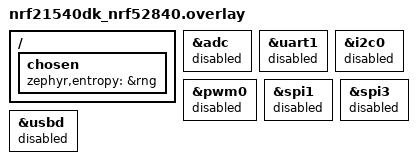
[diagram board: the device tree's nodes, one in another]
/* Copyright (c) 2021 Nordic Semiconductor ASA
 *
 * SPDX-License-Identifier: LicenseRef-Nordic-5-Clause
 */

/ {
	/*
	* In some default configurations within the nRF Connect SDK,
	* e.g. on nRF52840, the chosen zephyr,entropy node is &cryptocell.
	* This devicetree overlay ensures that default is overridden wherever it
	* is set, as this application uses the RNG node for entropy exclusively.
	*/
	chosen {
		zephyr,entropy = &rng;
	};
};

/* Disable unused peripherals to reduce power consumption */
&adc {
	status = "disabled";
};
&uart1 {
	status = "disabled";
};
&i2c0 {
	status = "disabled";
};
&pwm0 {
	status = "disabled";
};
&spi1 {
	status = "disabled";
};
&spi3 {
	status = "disabled";
};
&usbd {
	status = "disabled";
};
